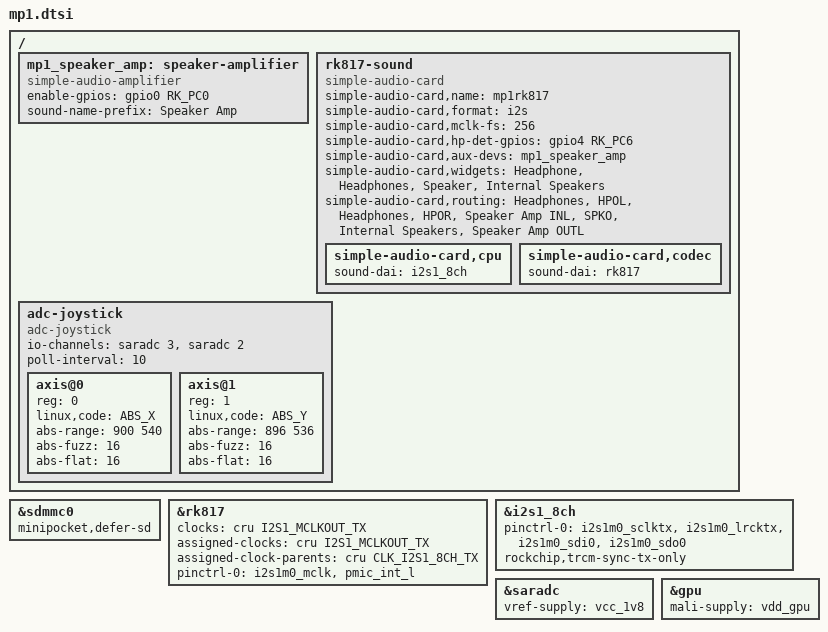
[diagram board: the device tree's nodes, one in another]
// SPDX-License-Identifier: (GPL-2.0-only OR MIT)
// MP1 board wiring from the stock-derived local MP1 platform description.
// The first launcher frames use the RAM root. Start SD after the second refresh.
&sdmmc0 { minipocket,defer-sd; };

/ {
    mp1_speaker_amp: speaker-amplifier {
        compatible = "simple-audio-amplifier";
        enable-gpios = <&gpio0 RK_PC0 GPIO_ACTIVE_HIGH>;
        sound-name-prefix = "Speaker Amp";
    };

    rk817-sound {
        compatible = "simple-audio-card";
        simple-audio-card,name = "mp1rk817";
        simple-audio-card,format = "i2s";
        simple-audio-card,mclk-fs = <256>;
        simple-audio-card,hp-det-gpios = <&gpio4 RK_PC6 GPIO_ACTIVE_HIGH>;
        simple-audio-card,aux-devs = <&mp1_speaker_amp>;
        simple-audio-card,widgets = "Headphone", "Headphones", "Speaker", "Internal Speakers";
        simple-audio-card,routing = "Headphones", "HPOL", "Headphones", "HPOR",
            "Speaker Amp INL", "SPKO", "Internal Speakers", "Speaker Amp OUTL";
        simple-audio-card,cpu { sound-dai = <&i2s1_8ch>; };
        simple-audio-card,codec { sound-dai = <&rk817>; };
    };

    adc-joystick {
        compatible = "adc-joystick";
        io-channels = <&saradc 3>, <&saradc 2>;
        #address-cells = <1>;
        #size-cells = <0>;
        poll-interval = <10>;

        axis@0 {
            reg = <0>;
            linux,code = <ABS_X>;
            abs-range = <900 540>;
            abs-fuzz = <16>;
            abs-flat = <16>;
        };
        axis@1 {
            reg = <1>;
            linux,code = <ABS_Y>;
            abs-range = <896 536>;
            abs-fuzz = <16>;
            abs-flat = <16>;
        };
    };
};

&rk817 {
    clocks = <&cru I2S1_MCLKOUT_TX>;
    clock-names = "mclk";
    assigned-clocks = <&cru I2S1_MCLKOUT_TX>;
    assigned-clock-parents = <&cru CLK_I2S1_8CH_TX>;
    #sound-dai-cells = <0>;
    pinctrl-0 = <&i2s1m0_mclk>, <&pmic_int_l>;
};

&i2s1_8ch {
    pinctrl-names = "default";
    pinctrl-0 = <&i2s1m0_sclktx>, <&i2s1m0_lrcktx>, <&i2s1m0_sdi0>, <&i2s1m0_sdo0>;
    rockchip,trcm-sync-tx-only;
    status = "okay";
};

&saradc {
    vref-supply = <&vcc_1v8>;
    status = "okay";
};

&gpu {
    mali-supply = <&vdd_gpu>;
    status = "okay";
};
